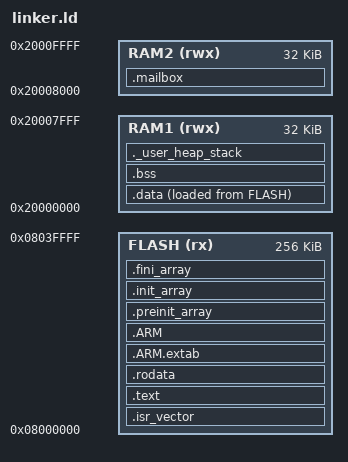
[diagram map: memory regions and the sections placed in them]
/*
 * linker.ld — Linker script for STM32WL55JC (Cortex-M4 core)
 * Author: jayis1
 * Copyright (C) 2026 jayis1. All rights reserved.
 * License: GPL-2.0
 *
 * Flash: 256 KB at 0x08000000
 * SRAM1: 32 KB at 0x20000000  (M4 application)
 * SRAM2: 32 KB at 0x20008000  (shared with M0+ radio core mailbox)
 */

ENTRY(Reset_Handler)

_estack = 0x20008000;      /* top of SRAM1 */

/* Minimum heap/stack */
_Min_Heap_Size  = 0x400;
_Min_Stack_Size = 0x800;

MEMORY
{
  FLASH (rx)  : ORIGIN = 0x08000000, LENGTH = 256K
  RAM1  (rwx) : ORIGIN = 0x20000000, LENGTH = 32K
  RAM2  (rwx) : ORIGIN = 0x20008000, LENGTH = 32K
}

SECTIONS
{
  .isr_vector :
  {
    . = ALIGN(4);
    KEEP(*(.isr_vector))
    . = ALIGN(4);
  } >FLASH

  .text :
  {
    . = ALIGN(4);
    *(.text)
    *(.text*)
    *(.glue_7)
    *(.glue_7t)
    *(.eh_frame)
    KEEP(*(.init))
    KEEP(*(.fini))
    . = ALIGN(4);
    _etext = .;
  } >FLASH

  .rodata :
  {
    . = ALIGN(4);
    *(.rodata)
    *(.rodata*)
    . = ALIGN(4);
  } >FLASH

  .ARM.extab :
  {
    *(.ARM.extab* .gnu.linkonce.armextab.*)
  } >FLASH

  .ARM :
  {
    __exidx_start = .;
    *(.ARM.exidx*)
    __exidx_end = .;
  } >FLASH

  .preinit_array :
  {
    PROVIDE_HIDDEN(__preinit_array_start = .);
    KEEP(*(.preinit_array*))
    PROVIDE_HIDDEN(__preinit_array_end = .);
  } >FLASH

  .init_array :
  {
    PROVIDE_HIDDEN(__init_array_start = .);
    KEEP(*(SORT(.init_array.*)))
    KEEP(*(.init_array*))
    PROVIDE_HIDDEN(__init_array_end = .);
  } >FLASH

  .fini_array :
  {
    PROVIDE_HIDDEN(__fini_array_start = .);
    KEEP(*(SORT(.fini_array.*)))
    KEEP(*(.fini_array*))
    PROVIDE_HIDDEN(__fini_array_end = .);
  } >FLASH

  _sidata = LOADADDR(.data);

  .data :
  {
    . = ALIGN(4);
    _sdata = .;
    *(.data)
    *(.data*)
    . = ALIGN(4);
    _edata = .;
  } >RAM1 AT> FLASH

  .bss :
  {
    . = ALIGN(4);
    _sbss = .;
    __bss_start__ = _sbss;
    *(.bss)
    *(.bss*)
    *(COMMON)
    . = ALIGN(4);
    _ebss = .;
    __bss_end__ = _ebss;
  } >RAM1

  /* Shared SRAM2 mailbox with M0+ radio core */
  .mailbox (NOLOAD) :
  {
    . = ALIGN(4);
    *(.mailbox)
    . = ALIGN(4);
  } >RAM2

  ._user_heap_stack (NOLOAD) :
  {
    . = ALIGN(8);
    PROVIDE(end = .);
    PROVIDE(_end = .);
    . = . + _Min_Heap_Size;
    . = . + _Min_Stack_Size;
    . = ALIGN(8);
  } >RAM1

  /DISCARD/ :
  {
    libc.a (*)
    libm.a (*)
    libgcc.a (*)
  }

  ARM_FLASH_BASE = 0x08000000;
  ARM_FLASH_SIZE = 256K;
  ARM_RAM_BASE   = 0x20000000;
  ARM_RAM_SIZE   = 64K;
}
